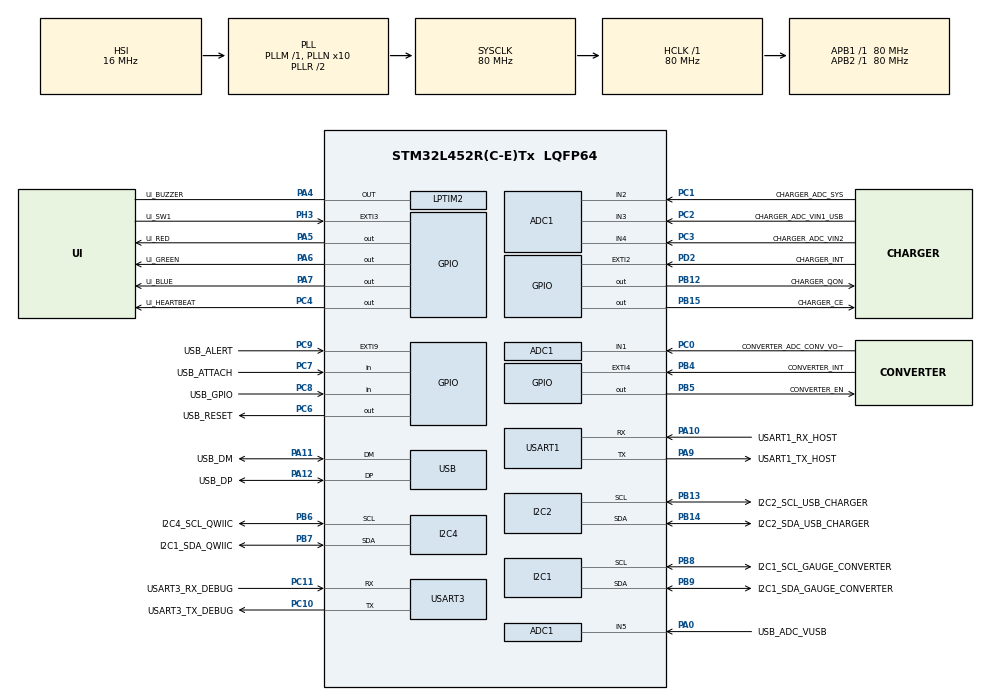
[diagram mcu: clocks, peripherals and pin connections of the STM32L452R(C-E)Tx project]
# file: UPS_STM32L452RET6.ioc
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ADC1.Channel-0\#ChannelRegularConversion=ADC_CHANNEL_VREFINT
ADC1.NbrOfConversionFlag=1
ADC1.OffsetNumber-0\#ChannelRegularConversion=ADC_OFFSET_NONE
ADC1.Rank-0\#ChannelRegularConversion=1
ADC1.SamplingTime-0\#ChannelRegularConversion=ADC_SAMPLETIME_2CYCLES_5
ADC1.master=1
FREERTOS.Tasks01=defaultTask,24,128,StartDefaultTask,Default,NULL,Dynamic,NULL,NULL
FREERTOS.configUSE_NEWLIB_REENTRANT=1
I2C1.Timing=0x10D19CE4
I2C2.Timing=0x10D19CE4
I2C4.Timing=0x10D19CE4
LPTIM2.ClockPrescaler=LPTIM_PRESCALER_DIV1
Mcu.Family=STM32L4
Mcu.Name=STM32L452R(C-E)Tx
Mcu.Package=LQFP64
NVIC.EXTI2_IRQn=true\:5\:0\:false\:false\:true\:true\:true\:true\:true
NVIC.EXTI9_5_IRQn=true\:5\:0\:false\:false\:true\:true\:true\:true\:true
NVIC.PriorityGroup=NVIC_PRIORITYGROUP_4
NVIC.TIM6_DAC_IRQn=true\:15\:0\:false\:false\:true\:false\:false\:true\:true
NVIC.TimeBase=TIM6_DAC_IRQn
NVIC.TimeBaseIP=TIM6
PA0.GPIO_Label=USB_ADC_VUSB 
PA0.Signal=ADCx_IN5
PA10.GPIO_Label=USART1_RX_HOST
PA10.Mode=Asynchronous
PA10.Signal=USART1_RX
PA11.GPIO_Label=USB_DM
PA11.Mode=Device
PA11.Signal=USB_DM
PA12.GPIO_Label=USB_DP
PA12.Mode=Device
PA12.Signal=USB_DP
PA13\ (JTMS/SWDIO).GPIO_Label=SWDIO_TMS
PA13\ (JTMS/SWDIO).Mode=Trace_Asynchronous_SW
PA13\ (JTMS/SWDIO).Signal=SYS_JTMS-SWDIO
PA14\ (JTCK/SWCLK).GPIO_Label=SWCLK_TCK
PA14\ (JTCK/SWCLK).Mode=Trace_Asynchronous_SW
PA14\ (JTCK/SWCLK).Signal=SYS_JTCK-SWCLK
PA4.GPIO_Label=UI_BUZZER
PA4.Mode=WaveformGeneration
PA4.Signal=LPTIM2_OUT
PA5.GPIO_Label=UI_RED
PA5.GPIO_PuPd=GPIO_PULLUP
PA5.Signal=GPIO_Output
PA6.GPIO_Label=UI_GREEN
PA6.GPIO_PuPd=GPIO_PULLUP
PA6.Signal=GPIO_Output
PA7.GPIO_Label=UI_BLUE
PA7.GPIO_PuPd=GPIO_PULLUP
PA7.Signal=GPIO_Output
PA9.GPIO_Label=USART1_TX_HOST
PA9.Mode=Asynchronous
PA9.Signal=USART1_TX
PB12.GPIO_Label=CHARGER_QON 
PB12.GPIO_PuPd=GPIO_PULLUP
PB12.Signal=GPIO_Output
PB13.GPIO_Label=I2C2_SCL_USB_CHARGER
PB13.Mode=I2C
PB13.Signal=I2C2_SCL
PB14.GPIO_Label=I2C2_SDA_USB_CHARGER
PB14.Mode=I2C
PB14.Signal=I2C2_SDA
PB15.GPIO_Label=CHARGER_CE 
PB15.GPIO_PuPd=GPIO_PULLUP
PB15.Signal=GPIO_Output
PB3\ (JTDO/TRACESWO).GPIO_Label=SWO_TDO
PB3\ (JTDO/TRACESWO).Mode=Trace_Asynchronous_SW
PB3\ (JTDO/TRACESWO).Signal=SYS_JTDO-SWO
PB4\ (NJTRST).GPIO_Label=CONVERTER_INT
PB4\ (NJTRST).GPIO_PuPd=GPIO_PULLDOWN
PB4\ (NJTRST).Signal=GPXTI4
PB5.GPIO_Label=CONVERTER_EN 
PB5.GPIO_PuPd=GPIO_PULLUP
PB5.Signal=GPIO_Output
PB6.GPIO_Label=I2C4_SCL_QWIIC
PB6.Mode=I2C
PB6.Signal=I2C4_SCL
PB7.GPIO_Label=I2C1_SDA_QWIIC
PB7.Mode=I2C
PB7.Signal=I2C4_SDA
PB8.GPIO_Label=I2C1_SCL_GAUGE_CONVERTER
PB8.Mode=I2C
PB8.Signal=I2C1_SCL
PB9.GPIO_Label=I2C1_SDA_GAUGE_CONVERTER
PB9.Mode=I2C
PB9.Signal=I2C1_SDA
PC0.GPIO_Label=CONVERTER_ADC_CONV_VOUT
PC0.Signal=ADCx_IN1
PC1.GPIO_Label=CHARGER_ADC_SYS
PC1.Signal=ADCx_IN2
PC10.GPIO_Label=USART3_TX_DEBUG
PC10.Mode=Asynchronous
PC10.Signal=USART3_TX
PC11.GPIO_Label=USART3_RX_DEBUG
PC11.Mode=Asynchronous
PC11.Signal=USART3_RX
PC14-OSC32_IN\ (PC14).Mode=LSE-External-Oscillator
PC14-OSC32_IN\ (PC14).Signal=RCC_OSC32_IN
PC15-OSC32_OUT\ (PC15).Mode=LSE-External-Oscillator
PC15-OSC32_OUT\ (PC15).Signal=RCC_OSC32_OUT
PC2.GPIO_Label=CHARGER_ADC_VIN1_USB
PC2.Signal=ADCx_IN3
PC3.GPIO_Label=CHARGER_ADC_VIN2
PC3.Signal=ADCx_IN4
PC4.GPIO_Label=UI_HEARTBEAT
PC4.GPIO_PuPd=GPIO_PULLUP
PC4.Signal=GPIO_Output
PC6.GPIO_Label=USB_RESET
PC6.GPIO_PuPd=GPIO_PULLUP
PC6.Signal=GPIO_Output
PC7.GPIO_Label=USB_ATTACH
PC7.GPIO_PuPd=GPIO_PULLDOWN
PC7.Signal=GPIO_Input
PC8.GPIO_Label=USB_GPIO
PC8.GPIO_PuPd=GPIO_PULLDOWN
PC8.Signal=GPIO_Input
PC9.GPIO_Label=USB_ALERT 
PC9.GPIO_ModeDefaultEXTI=GPIO_MODE_IT_RISING
PC9.GPIO_PuPd=GPIO_PULLDOWN
PC9.Signal=GPXTI9
PD2.GPIO_Label=CHARGER_INT 
PD2.GPIO_ModeDefaultEXTI=GPIO_MODE_IT_RISING
PD2.GPIO_PuPd=GPIO_PULLDOWN
PD2.Signal=GPXTI2
PH0-OSC_IN\ (PH0).GPIO_Label=CLK_8MHZ
PH0-OSC_IN\ (PH0).Mode=HSE-External-Clock-Source
PH0-OSC_IN\ (PH0).Signal=RCC_OSC_IN
PH3-BOOT0\ (BOOT0).GPIO_Label=UI_SW1
PH3-BOOT0\ (BOOT0).GPIO_PuPd=GPIO_PULLDOWN
PH3-BOOT0\ (BOOT0).Signal=GPXTI3
ProjectManager.HeapSize=0x200
ProjectManager.StackSize=0x400
ProjectManager.TargetToolchain=STM32CubeIDE
RCC.ADCFreq_Value=64000000
RCC.AHBFreq_Value=80000000
RCC.APB1Freq_Value=80000000
RCC.APB1TimFreq_Value=80000000
RCC.APB2Freq_Value=80000000
RCC.APB2TimFreq_Value=80000000
RCC.CK48CLockSelection=RCC_USBCLKSOURCE_HSI48
RCC.CortexFreq_Value=80000000
RCC.HCLKFreq_Value=80000000
RCC.HSE_VALUE=8000000
RCC.HSI48_VALUE=48000000
RCC.HSI_VALUE=16000000
RCC.LPTIM2CLockSelection=RCC_LPTIM2CLKSOURCE_LSI
RCC.MSI_VALUE=4000000
RCC.PLLN=10
RCC.PLLSourceVirtual=RCC_PLLSOURCE_HSI
RCC.RTCClockSelection=RCC_RTCCLKSOURCE_LSE
RCC.SYSCLKFreq_VALUE=80000000
RCC.SYSCLKSource=RCC_SYSCLKSOURCE_PLLCLK
RCC.USBFreq_Value=48000000
RCC.VCOOutputFreq_Value=160000000
SH.ADCx_IN1.0=ADC1_IN1,IN1-Single-Ended
SH.ADCx_IN2.0=ADC1_IN2,IN2-Single-Ended
SH.ADCx_IN3.0=ADC1_IN3,IN3-Single-Ended
SH.ADCx_IN4.0=ADC1_IN4,IN4-Single-Ended
SH.ADCx_IN5.0=ADC1_IN5,IN5-Single-Ended
USART1.VirtualMode-Asynchronous=VM_ASYNC
USART3.VirtualMode-Asynchronous=VM_ASYNC
VP_ADC1_TempSens_Input.Mode=IN-TempSens
VP_ADC1_Vbat_Input.Mode=IN-Vbat
VP_ADC1_Vref_Input.Mode=IN-Vrefint
VP_FREERTOS_VS_CMSIS_V2.Mode=CMSIS_V2
VP_IWDG_VS_IWDG.Mode=IWDG_Activate
VP_LPTIM2_VS_LPTIM_counterModeInternalClock.Mode=Counts__internal_clock_event_00
VP_RTC_VS_RTC_Activate.Mode=RTC_Enabled
VP_RTC_VS_RTC_Calendar.Mode=RTC_Calendar
VP_SYS_VS_tim6.Mode=TIM6
VP_TIM1_VS_ClockSourceINT.Mode=Internal
board=custom

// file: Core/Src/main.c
/* USER CODE BEGIN Header */
/**
  ******************************************************************************
  * @file           : main.c
  * @brief          : Main program body
  ******************************************************************************
  * @attention
  *
  * Copyright (c) 2026 STMicroelectronics.
  * All rights reserved.
  *
  * This software is licensed under terms that can be found in the LICENSE file
  * in the root directory of this software component.
  * If no LICENSE file comes with this software, it is provided AS-IS.
  *
  ******************************************************************************
  */
/* USER CODE END Header */
#include "main.h"
#include "cmsis_os.h"
#include "adc.h"
#include "i2c.h"
#include "iwdg.h"
#include "lptim.h"
#include "rtc.h"
#include "tim.h"
#include "usart.h"
#include "usb.h"
#include "gpio.h"

/* USER CODE BEGIN PD */

/* ----- User configuration for buzzer----- */
#define LPTIM2_PWM_FREQ_HZ     (4000U)       /* Target PWM frequency */
#define LPTIM2_CLK_HZ          (32000U)      /* We select LSI 32KHz as LPTIM2 kernel clock */
#define LPTIM2_PERIOD          ((LPTIM2_CLK_HZ / LPTIM2_PWM_FREQ_HZ) - 1U)  /* 7 */
#define LPTIM2_PULSE           (((LPTIM2_PERIOD + 1U) / 2U) - 1U)           /* 3 -> ~50% */

/* USER CODE END PD */

void SystemClock_Config(void);
void MX_FREERTOS_Init(void);

int main(void)
{

  /* MCU Configuration--------------------------------------------------------*/

  /* Reset of all peripherals, Initializes the Flash interface and the Systick. */
  HAL_Init();

  /* Configure the system clock */
  SystemClock_Config();

  /* Initialize all configured peripherals */
  MX_GPIO_Init();
  MX_ADC1_Init();
  MX_I2C2_Init();
  MX_I2C4_Init();
  MX_IWDG_Init();
  MX_RTC_Init();
  MX_USART1_UART_Init();
  MX_USB_PCD_Init();
  MX_USART3_UART_Init();
  MX_LPTIM2_Init();
  MX_TIM1_Init();
  MX_I2C1_Init();
  /* USER CODE BEGIN 2 */

  /* Start PWM: ARR=7, CMP=3 -> 4 kHz, ~50% duty */
  if (HAL_LPTIM_PWM_Start(&hlptim2, LPTIM2_PERIOD, LPTIM2_PULSE) != HAL_OK)  /* PWM start */
  {
      Error_Handler();
  }

  /* USER CODE END 2 */

  /* Init scheduler */
  osKernelInitialize();  /* Call init function for freertos objects (in cmsis_os2.c) */
  MX_FREERTOS_Init();

  /* Start scheduler */
  osKernelStart();

  /* We should never get here as control is now taken by the scheduler */

  /* Infinite loop */
  while (1)
  {

    /* USER CODE BEGIN 3 */

	  /* Low-power hint: you can sleep here; LPTIM keeps running */
      __WFI();

  }
  /* USER CODE END 3 */
}

void SystemClock_Config(void)
{
  RCC_OscInitTypeDef RCC_OscInitStruct = {0};
  RCC_ClkInitTypeDef RCC_ClkInitStruct = {0};

  /** Configure the main internal regulator output voltage
  */
  if (HAL_PWREx_ControlVoltageScaling(PWR_REGULATOR_VOLTAGE_SCALE1) != HAL_OK)
  {
    Error_Handler();
  }

  /** Configure LSE Drive Capability
  */
  HAL_PWR_EnableBkUpAccess();
  __HAL_RCC_LSEDRIVE_CONFIG(RCC_LSEDRIVE_LOW);

  /** Initializes the RCC Oscillators according to the specified parameters
  * in the RCC_OscInitTypeDef structure.
  */
  RCC_OscInitStruct.OscillatorType = RCC_OSCILLATORTYPE_HSI48|RCC_OSCILLATORTYPE_HSI
                              |RCC_OSCILLATORTYPE_LSI|RCC_OSCILLATORTYPE_LSE;
  RCC_OscInitStruct.LSEState = RCC_LSE_ON;
  RCC_OscInitStruct.HSIState = RCC_HSI_ON;
  RCC_OscInitStruct.HSI48State = RCC_HSI48_ON;
  RCC_OscInitStruct.HSICalibrationValue = 64;
  RCC_OscInitStruct.LSIState = RCC_LSI_ON;
  RCC_OscInitStruct.PLL.PLLState = RCC_PLL_ON;
  RCC_OscInitStruct.PLL.PLLSource = RCC_PLLSOURCE_HSI;
  RCC_OscInitStruct.PLL.PLLM = 1;
  RCC_OscInitStruct.PLL.PLLN = 10;
  RCC_OscInitStruct.PLL.PLLP = RCC_PLLP_DIV7;
  RCC_OscInitStruct.PLL.PLLQ = RCC_PLLQ_DIV2;
  RCC_OscInitStruct.PLL.PLLR = RCC_PLLR_DIV2;
  if (HAL_RCC_OscConfig(&RCC_OscInitStruct) != HAL_OK)
  {
    Error_Handler();
  }

  /** Initializes the CPU, AHB and APB buses clocks
  */
  RCC_ClkInitStruct.ClockType = RCC_CLOCKTYPE_HCLK|RCC_CLOCKTYPE_SYSCLK
                              |RCC_CLOCKTYPE_PCLK1|RCC_CLOCKTYPE_PCLK2;
  RCC_ClkInitStruct.SYSCLKSource = RCC_SYSCLKSOURCE_PLLCLK;
  RCC_ClkInitStruct.AHBCLKDivider = RCC_SYSCLK_DIV1;
  RCC_ClkInitStruct.APB1CLKDivider = RCC_HCLK_DIV1;
  RCC_ClkInitStruct.APB2CLKDivider = RCC_HCLK_DIV1;

  if (HAL_RCC_ClockConfig(&RCC_ClkInitStruct, FLASH_LATENCY_4) != HAL_OK)
  {
    Error_Handler();
  }
}

void HAL_TIM_PeriodElapsedCallback(TIM_HandleTypeDef *htim)
{
  if (htim->Instance == TIM6)
  {
    HAL_IncTick();
  }
}

void Error_Handler(void)
{
  __disable_irq();
  while (1)
  {
  }
}
